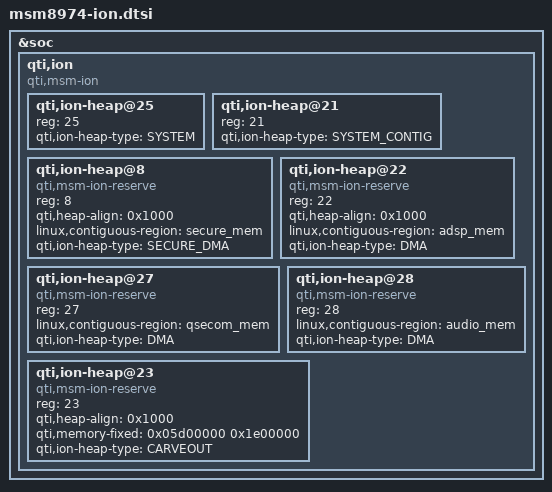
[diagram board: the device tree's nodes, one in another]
/* Copyright (c) 2012-2013, The Linux Foundation. All rights reserved.
 *
 * This program is free software; you can redistribute it and/or modify
 * it under the terms of the GNU General Public License version 2 and
 * only version 2 as published by the Free Software Foundation.
 *
 * This program is distributed in the hope that it will be useful,
 * but WITHOUT ANY WARRANTY; without even the implied warranty of
 * MERCHANTABILITY or FITNESS FOR A PARTICULAR PURPOSE.  See the
 * GNU General Public License for more details.
 */

&soc {
	qti,ion {
		compatible = "qti,msm-ion";
		#address-cells = <1>;
		#size-cells = <0>;

		qti,ion-heap@25 {
			reg = <25>;
			qti,ion-heap-type = "SYSTEM";
		};

		qti,ion-heap@21 {
			reg = <21>;
			qti,ion-heap-type = "SYSTEM_CONTIG";
		};

		qti,ion-heap@8 { /* CP_MM HEAP */
			compatible = "qti,msm-ion-reserve";
			reg = <8>;
			qti,heap-align = <0x1000>;
			linux,contiguous-region = <&secure_mem>;
			qti,ion-heap-type = "SECURE_DMA";
		};

		qti,ion-heap@22 { /* adsp heap */
			compatible = "qti,msm-ion-reserve";
			reg = <22>;
			qti,heap-align = <0x1000>;
			linux,contiguous-region = <&adsp_mem>;
			qti,ion-heap-type = "DMA";
		};

		qti,ion-heap@27 { /* QSECOM HEAP */
			compatible = "qti,msm-ion-reserve";
			reg = <27>;
			linux,contiguous-region = <&qsecom_mem>;
			qti,ion-heap-type = "DMA";
		};

		qti,ion-heap@28 { /* AUDIO HEAP */
			compatible = "qti,msm-ion-reserve";
			reg = <28>;
			linux,contiguous-region = <&audio_mem>;
			qti,ion-heap-type = "DMA";
		};

		qti,ion-heap@23 { /* OTHER PIL HEAP */
			compatible = "qti,msm-ion-reserve";
			reg = <23>;
			qti,heap-align = <0x1000>;
			qti,memory-fixed = <0x05d00000 0x1e00000>;
			qti,ion-heap-type = "CARVEOUT";
		};
	};
};
